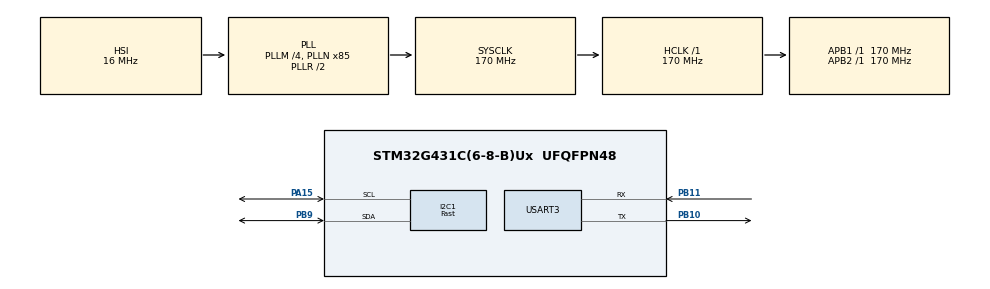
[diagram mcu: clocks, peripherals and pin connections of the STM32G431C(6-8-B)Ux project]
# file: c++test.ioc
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FREERTOS.Tasks01=defaultTask,24,128,StartDefaultTask,Default,NULL,Dynamic,NULL,NULL
I2C1.I2C_Speed_Mode=I2C_Fast
I2C1.Timing=0x10802D9B
Mcu.Family=STM32G4
Mcu.Name=STM32G431C(6-8-B)Ux
Mcu.Package=UFQFPN48
NVIC.PriorityGroup=NVIC_PRIORITYGROUP_4
NVIC.USART3_IRQn=true\:5\:0\:false\:false\:true\:true\:true\:true\:true
PA13.Mode=Serial_Wire
PA13.Signal=SYS_JTMS-SWDIO
PA14.Mode=Serial_Wire
PA14.Signal=SYS_JTCK-SWCLK
PA15.Mode=I2C
PA15.Signal=I2C1_SCL
PB10.Mode=Asynchronous
PB10.Signal=USART3_TX
PB11.Mode=Asynchronous
PB11.Signal=USART3_RX
PB9.Mode=I2C
PB9.Signal=I2C1_SDA
PF0-OSC_IN.Mode=HSE-External-Oscillator
PF0-OSC_IN.Signal=RCC_OSC_IN
PF1-OSC_OUT.Mode=HSE-External-Oscillator
PF1-OSC_OUT.Signal=RCC_OSC_OUT
ProjectManager.HeapSize=0x200
ProjectManager.StackSize=0x400
ProjectManager.TargetToolchain=MDK-ARM V5.32
RCC.ADC12Freq_Value=170000000
RCC.AHBFreq_Value=170000000
RCC.APB1Freq_Value=170000000
RCC.APB1TimFreq_Value=170000000
RCC.APB2Freq_Value=170000000
RCC.APB2TimFreq_Value=170000000
RCC.CortexFreq_Value=170000000
RCC.EXTERNAL_CLOCK_VALUE=12288000
RCC.HCLKFreq_Value=170000000
RCC.HSE_VALUE=8000000
RCC.HSI48_VALUE=48000000
RCC.HSI_VALUE=16000000
RCC.LSE_VALUE=32768
RCC.PLLM=RCC_PLLM_DIV4
RCC.PLLN=85
RCC.SYSCLKFreq_VALUE=170000000
RCC.SYSCLKSource=RCC_SYSCLKSOURCE_PLLCLK
RCC.USBFreq_Value=170000000
RCC.VCOOutputFreq_Value=340000000
USART3.VirtualMode-Asynchronous=VM_ASYNC
VP_FREERTOS_VS_CMSIS_V2.Mode=CMSIS_V2
VP_SYS_VS_DBSignals.Mode=DisableDeadBatterySignals
board=custom

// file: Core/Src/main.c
/* USER CODE BEGIN Header */
/**
 ******************************************************************************
 * @file           : main.c
 * @brief          : Main program body
 ******************************************************************************
 * @attention
 *
 * Copyright (c) 2024 STMicroelectronics.
 * All rights reserved.
 *
 * This software is licensed under terms that can be found in the LICENSE file
 * in the root directory of this software component.
 * If no LICENSE file comes with this software, it is provided AS-IS.
 *
 ******************************************************************************
 */
/* USER CODE END Header */
#include "main.h"
#include "cmsis_os.h"
#include "i2c.h"
#include "usart.h"
#include "gpio.h"

/* USER CODE BEGIN Includes */
#include "comm.h"
#include "userMain.h"
/* USER CODE END Includes */

void SystemClock_Config(void);
void MX_FREERTOS_Init(void);

int main(void)
{

  /* MCU Configuration--------------------------------------------------------*/

  /* Reset of all peripherals, Initializes the Flash interface and the Systick. */
  HAL_Init();

  /* Configure the system clock */
  SystemClock_Config();

  /* Initialize all configured peripherals */
  MX_GPIO_Init();
  MX_USART3_UART_Init();
  MX_I2C1_Init();
  /* USER CODE BEGIN 2 */
  HAL_UART_Receive_IT(&huart3, (uint8_t *)&aRxBuffer, 1);
  /* USER CODE END 2 */

  /* Init scheduler */
  osKernelInitialize();  /* Call init function for freertos objects (in freertos.c) */
  MX_FREERTOS_Init();

  /* Start scheduler */
  osKernelStart();

  /* We should never get here as control is now taken by the scheduler */
  /* Infinite loop */
  while (1)
  {

  }
}

void SystemClock_Config(void)
{
  RCC_OscInitTypeDef RCC_OscInitStruct = {0};
  RCC_ClkInitTypeDef RCC_ClkInitStruct = {0};

  /** Configure the main internal regulator output voltage
  */
  HAL_PWREx_ControlVoltageScaling(PWR_REGULATOR_VOLTAGE_SCALE1_BOOST);

  /** Initializes the RCC Oscillators according to the specified parameters
  * in the RCC_OscInitTypeDef structure.
  */
  RCC_OscInitStruct.OscillatorType = RCC_OSCILLATORTYPE_HSI;
  RCC_OscInitStruct.HSIState = RCC_HSI_ON;
  RCC_OscInitStruct.HSICalibrationValue = RCC_HSICALIBRATION_DEFAULT;
  RCC_OscInitStruct.PLL.PLLState = RCC_PLL_ON;
  RCC_OscInitStruct.PLL.PLLSource = RCC_PLLSOURCE_HSI;
  RCC_OscInitStruct.PLL.PLLM = RCC_PLLM_DIV4;
  RCC_OscInitStruct.PLL.PLLN = 85;
  RCC_OscInitStruct.PLL.PLLP = RCC_PLLP_DIV2;
  RCC_OscInitStruct.PLL.PLLQ = RCC_PLLQ_DIV2;
  RCC_OscInitStruct.PLL.PLLR = RCC_PLLR_DIV2;
  if (HAL_RCC_OscConfig(&RCC_OscInitStruct) != HAL_OK)
  {
    Error_Handler();
  }

  /** Initializes the CPU, AHB and APB buses clocks
  */
  RCC_ClkInitStruct.ClockType = RCC_CLOCKTYPE_HCLK|RCC_CLOCKTYPE_SYSCLK
                              |RCC_CLOCKTYPE_PCLK1|RCC_CLOCKTYPE_PCLK2;
  RCC_ClkInitStruct.SYSCLKSource = RCC_SYSCLKSOURCE_PLLCLK;
  RCC_ClkInitStruct.AHBCLKDivider = RCC_SYSCLK_DIV1;
  RCC_ClkInitStruct.APB1CLKDivider = RCC_HCLK_DIV1;
  RCC_ClkInitStruct.APB2CLKDivider = RCC_HCLK_DIV1;

  if (HAL_RCC_ClockConfig(&RCC_ClkInitStruct, FLASH_LATENCY_4) != HAL_OK)
  {
    Error_Handler();
  }
}

void Error_Handler(void)
{
  __disable_irq();
  while (1)
  {
  }
}

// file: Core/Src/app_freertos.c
/* USER CODE BEGIN Header */
/**
 ******************************************************************************
 * File Name          : app_freertos.c
 * Description        : Code for freertos applications
 ******************************************************************************
 * @attention
 *
 * Copyright (c) 2024 STMicroelectronics.
 * All rights reserved.
 *
 * This software is licensed under terms that can be found in the LICENSE file
 * in the root directory of this software component.
 * If no LICENSE file comes with this software, it is provided AS-IS.
 *
 ******************************************************************************
 */
/* USER CODE END Header */

#include "FreeRTOS.h"
#include "task.h"
#include "main.h"
#include "cmsis_os.h"

/* Definitions for defaultTask */
osThreadId_t defaultTaskHandle;
const osThreadAttr_t defaultTask_attributes = {
  .name = "defaultTask",
  .priority = (osPriority_t) osPriorityNormal,
  .stack_size = 128 * 4
};

void StartDefaultTask(void *argument);

void MX_FREERTOS_Init(void); /* (MISRA C 2004 rule 8.1) */

void MX_FREERTOS_Init(void) {

  /* Create the thread(s) */
  /* creation of defaultTask */
  defaultTaskHandle = osThreadNew(StartDefaultTask, NULL, &defaultTask_attributes);

}

void StartDefaultTask(void *argument)
{
  /* USER CODE BEGIN StartDefaultTask */
  userMain();

  vTaskDelete(defaultTaskHandle);
  /* USER CODE END StartDefaultTask */
}
